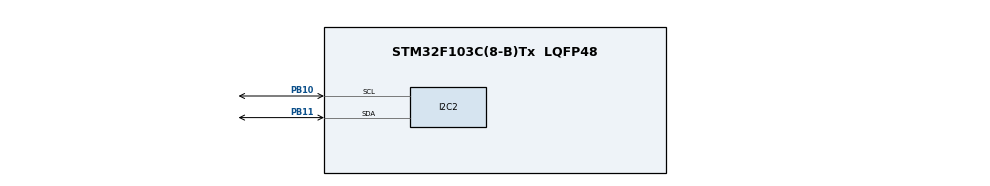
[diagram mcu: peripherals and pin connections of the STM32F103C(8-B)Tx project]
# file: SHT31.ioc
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Mcu.Family=STM32F1
Mcu.Name=STM32F103C(8-B)Tx
Mcu.Package=LQFP48
NVIC.PriorityGroup=NVIC_PRIORITYGROUP_4
PA13.Mode=Serial_Wire
PA13.Signal=SYS_JTMS-SWDIO
PA14.Mode=Serial_Wire
PA14.Signal=SYS_JTCK-SWCLK
PB10.Mode=I2C
PB10.Signal=I2C2_SCL
PB11.Mode=I2C
PB11.Signal=I2C2_SDA
PD0-OSC_IN.Mode=HSE-External-Oscillator
PD0-OSC_IN.Signal=RCC_OSC_IN
PD1-OSC_OUT.Mode=HSE-External-Oscillator
PD1-OSC_OUT.Signal=RCC_OSC_OUT
ProjectManager.HeapSize=0x200
ProjectManager.StackSize=0x400
ProjectManager.TargetToolchain=STM32CubeIDE
RCC.APB1Freq_Value=8000000
RCC.APB2Freq_Value=8000000
board=custom

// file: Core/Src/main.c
/* USER CODE BEGIN Header */
/**
  ******************************************************************************
  * @file           : main.c
  * @brief          : Main program body
  ******************************************************************************
  * @attention
  *
  * <h2><center>&copy; Copyright (c) 2019 STMicroelectronics.
  * All rights reserved.</center></h2>
  *
  * This software component is licensed by ST under BSD 3-Clause license,
  * the "License"; You may not use this file except in compliance with the
  * License. You may obtain a copy of the License at:
  *                        opensource.org/licenses/BSD-3-Clause
  *
  ******************************************************************************
  */
/* USER CODE END Header */

#include "main.h"

/* USER CODE BEGIN Includes */
#define thermal_address 0x44
/* USER CODE END Includes */

/* USER CODE BEGIN PTD */
uint16_t ID=0;
uint8_t data[2] = {0x24,0x00};
unsigned char readbuff[7];
int16_t temp_shift[9];
int16_t temp_temp[9];
unsigned char readbuff_2[19];
int16_t temp_shift_2[9];
int16_t temp_temp_2[9];
int temp;
float cTemp;
int i;

/* USER CODE END PTD */

I2C_HandleTypeDef hi2c2;

void SystemClock_Config(void);
static void MX_GPIO_Init(void);
static void MX_I2C2_Init(void);

int main(void)
{

  /* MCU Configuration--------------------------------------------------------*/

  /* Reset of all peripherals, Initializes the Flash interface and the Systick. */
  HAL_Init();

  /* Configure the system clock */
  SystemClock_Config();

  /* Initialize all configured peripherals */
  MX_GPIO_Init();
  MX_I2C2_Init();

  /* Infinite loop */
  while (1)
  {
		HAL_Delay(50);
		HAL_I2C_Master_Transmit(&hi2c2,thermal_address<<1,data,2,50);
		HAL_Delay(50);
		HAL_I2C_Master_Receive(&hi2c2,thermal_address<<1,readbuff,6,50);
		temp = (readbuff[0] * 256) + readbuff[1];
		cTemp = -45.0 + (175.0 * temp / 65535.0);        //final temperature value
  }
}

void SystemClock_Config(void)
{
  RCC_OscInitTypeDef RCC_OscInitStruct = {0};
  RCC_ClkInitTypeDef RCC_ClkInitStruct = {0};

  /** Initializes the CPU, AHB and APB busses clocks
  */
  RCC_OscInitStruct.OscillatorType = RCC_OSCILLATORTYPE_HSI;
  RCC_OscInitStruct.HSIState = RCC_HSI_ON;
  RCC_OscInitStruct.HSICalibrationValue = RCC_HSICALIBRATION_DEFAULT;
  RCC_OscInitStruct.PLL.PLLState = RCC_PLL_NONE;
  if (HAL_RCC_OscConfig(&RCC_OscInitStruct) != HAL_OK)
  {
    Error_Handler();
  }
  /** Initializes the CPU, AHB and APB busses clocks
  */
  RCC_ClkInitStruct.ClockType = RCC_CLOCKTYPE_HCLK|RCC_CLOCKTYPE_SYSCLK
                              |RCC_CLOCKTYPE_PCLK1|RCC_CLOCKTYPE_PCLK2;
  RCC_ClkInitStruct.SYSCLKSource = RCC_SYSCLKSOURCE_HSI;
  RCC_ClkInitStruct.AHBCLKDivider = RCC_SYSCLK_DIV1;
  RCC_ClkInitStruct.APB1CLKDivider = RCC_HCLK_DIV1;
  RCC_ClkInitStruct.APB2CLKDivider = RCC_HCLK_DIV1;

  if (HAL_RCC_ClockConfig(&RCC_ClkInitStruct, FLASH_LATENCY_0) != HAL_OK)
  {
    Error_Handler();
  }
}

static void MX_I2C2_Init(void)
{

  hi2c2.Instance = I2C2;
  hi2c2.Init.ClockSpeed = 100000;
  hi2c2.Init.DutyCycle = I2C_DUTYCYCLE_2;
  hi2c2.Init.OwnAddress1 = 0;
  hi2c2.Init.AddressingMode = I2C_ADDRESSINGMODE_7BIT;
  hi2c2.Init.DualAddressMode = I2C_DUALADDRESS_DISABLE;
  hi2c2.Init.OwnAddress2 = 0;
  hi2c2.Init.GeneralCallMode = I2C_GENERALCALL_DISABLE;
  hi2c2.Init.NoStretchMode = I2C_NOSTRETCH_DISABLE;
  if (HAL_I2C_Init(&hi2c2) != HAL_OK)
  {
    Error_Handler();
  }

}

static void MX_GPIO_Init(void)
{

  /* GPIO Ports Clock Enable */
  __HAL_RCC_GPIOD_CLK_ENABLE();
  __HAL_RCC_GPIOB_CLK_ENABLE();
  __HAL_RCC_GPIOA_CLK_ENABLE();

}

void Error_Handler(void)
{
}

/************************ (C) COPYRIGHT STMicroelectronics *****END OF FILE****/
